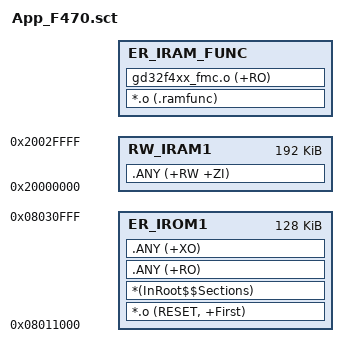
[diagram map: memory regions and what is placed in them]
; App scatter file for GD32F470VET6 (APP1 region)
; APP1 : 0x08011000 - 0x08030FFF (128KB) — 赛题 2.5 节
; After BL(64KB, 0x08000000) + Param(4KB, 0x08010000)

LR_IROM1 0x08011000 0x00020000  {
  ER_IROM1 0x08011000 0x00020000  {
   *.o (RESET, +First)
   *(InRoot$$Sections)
   .ANY (+RO)
   .ANY (+XO)
  }
  RW_IRAM1 0x20000000 0x00030000  {
   .ANY (+RW +ZI)
  }
  ER_IRAM_FUNC +0  {
   *.o (.ramfunc)
   gd32f4xx_fmc.o (+RO)
  }
}
